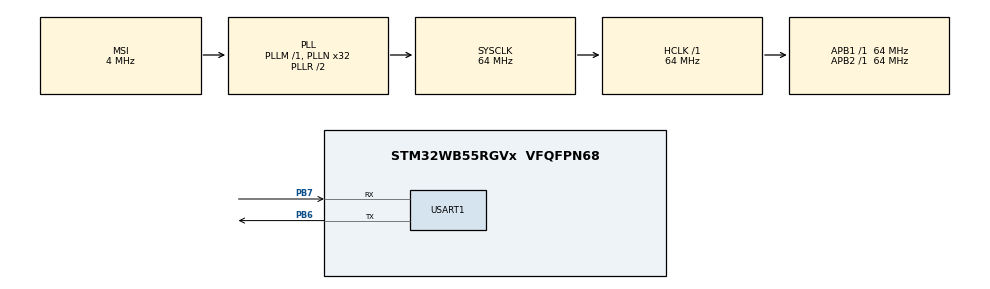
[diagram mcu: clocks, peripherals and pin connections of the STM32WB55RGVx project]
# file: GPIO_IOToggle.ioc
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Mcu.Family=STM32WB
Mcu.Name=STM32WB55RGVx
Mcu.Package=VFQFPN68
NVIC.PriorityGroup=NVIC_PRIORITYGROUP_4
PB6.Mode=Asynchronous
PB6.Signal=USART1_TX
PB7.Mode=Asynchronous
PB7.Signal=USART1_RX
ProjectManager.HeapSize=0x200
ProjectManager.StackSize=0x400
ProjectManager.TargetToolchain=STM32CubeIDE
RCC.ADCFreq_Value=16000000
RCC.AHB2CLKDivider=RCC_SYSCLK_DIV2
RCC.AHBFreq_Value=64000000
RCC.APB1Freq_Value=64000000
RCC.APB1TimFreq_Value=64000000
RCC.APB2Freq_Value=64000000
RCC.APB2TimFreq_Value=64000000
RCC.APB3Freq_Value=16000000
RCC.CodegenConfigPeriph=false
RCC.CortexFreq_Value=64000000
RCC.HCLKFreq_Value=64000000
RCC.HSE_VALUE=8000000
RCC.HSI48_VALUE=48000000
RCC.HSI_VALUE=16000000
RCC.LSE_VALUE=32768
RCC.MSI_VALUE=4000000
RCC.PLLN=32
RCC.PLLP=RCC_PLLP_DIV5
RCC.PLLQ=4
RCC.SYSCLKFreq_VALUE=64000000
RCC.SYSCLKSource=RCC_SYSCLKSOURCE_PLLCLK
RCC.USBFreq_Value=16000000
RCC.VCOOutputFreq_Value=128000000
USART1.VirtualMode-Asynchronous=VM_ASYNC
board=custom

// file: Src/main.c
/* USER CODE BEGIN Header */
/**
  ******************************************************************************
  * @file    GPIO/GPIO_IOToggle/Src/main.c
  * @author  MCD Application Team
  * @brief   This example describes how to configure and use GPIOs through
  *          the STM32WBxx HAL API.
  ******************************************************************************
  * @attention
  *
  * <h2><center>&copy; Copyright (c) 2019 STMicroelectronics.
  * All rights reserved.</center></h2>
  *
  * This software component is licensed by ST under BSD 3-Clause license,
  * the "License"; You may not use this file except in compliance with the
  * License. You may obtain a copy of the License at:
  *                        opensource.org/licenses/BSD-3-Clause
  *
  ******************************************************************************
  */
/* USER CODE END Header */
#include "main.h"

UART_HandleTypeDef huart1;

/* USER CODE BEGIN PV */
static GPIO_InitTypeDef  GPIO_InitStruct;

/* USER CODE END PV */

void SystemClock_Config(void);
static void MX_GPIO_Init(void);
static void MX_USART1_UART_Init(void);

int main(void)
{
  /* USER CODE BEGIN 1 */
  /* STM32WBxx HAL library initialization:
       - Configure the Flash prefetch
       - Systick timer is configured by default as source of time base, but user
         can eventually implement his proper time base source (a general purpose
         timer for example or other time source), keeping in mind that Time base
         duration should be kept 1ms since PPP_TIMEOUT_VALUEs are defined and
         handled in milliseconds basis.
       - Set NVIC Group Priority to 4
       - Low Level Initialization
     */
  /* USER CODE END 1 */

  /* MCU Configuration--------------------------------------------------------*/

  /* Reset of all peripherals, Initializes the Flash interface and the Systick. */
  HAL_Init();

  /* Configure the system clock */
  SystemClock_Config();

  /* Initialize all configured peripherals */
  MX_GPIO_Init();
  MX_USART1_UART_Init();
  /* USER CODE BEGIN 2 */

   /* -1- Enable GPIO Clock (to be able to program the configuration registers) */

  /* USER CODE END 2 */

  /* Infinite loop */
  while (1)
  {
  	uint8_t TxDataGP[32] = {0x55,0xAA,2,17,2,96,112,120,120,112,96,96,112,120,120,120,120,112,96,96,112,120,120,120,120,112,96,132,0,32,120,0,0,0,4,0,0,0};
  	HAL_UART_Transmit(&huart1, (uint8_t*)TxDataGP, 32,100);
    HAL_Delay(1000);

  }
  /* USER CODE END 3 */
}

void SystemClock_Config(void)
{
  RCC_OscInitTypeDef RCC_OscInitStruct = {0};
  RCC_ClkInitTypeDef RCC_ClkInitStruct = {0};

  /** Initializes the RCC Oscillators according to the specified parameters
  * in the RCC_OscInitTypeDef structure.
  */
  RCC_OscInitStruct.OscillatorType = RCC_OSCILLATORTYPE_MSI;
  RCC_OscInitStruct.MSIState = RCC_MSI_ON;
  RCC_OscInitStruct.MSICalibrationValue = RCC_MSICALIBRATION_DEFAULT;
  RCC_OscInitStruct.MSIClockRange = RCC_MSIRANGE_6;
  RCC_OscInitStruct.PLL.PLLState = RCC_PLL_ON;
  RCC_OscInitStruct.PLL.PLLSource = RCC_PLLSOURCE_MSI;
  RCC_OscInitStruct.PLL.PLLM = RCC_PLLM_DIV1;
  RCC_OscInitStruct.PLL.PLLN = 32;
  RCC_OscInitStruct.PLL.PLLP = RCC_PLLP_DIV5;
  RCC_OscInitStruct.PLL.PLLR = RCC_PLLR_DIV2;
  RCC_OscInitStruct.PLL.PLLQ = 4;
  if (HAL_RCC_OscConfig(&RCC_OscInitStruct) != HAL_OK)
  {
    Error_Handler();
  }
  /** Configure the SYSCLKSource, HCLK, PCLK1 and PCLK2 clocks dividers
  */
  RCC_ClkInitStruct.ClockType = RCC_CLOCKTYPE_HCLK4|RCC_CLOCKTYPE_HCLK2
                              |RCC_CLOCKTYPE_HCLK|RCC_CLOCKTYPE_SYSCLK
                              |RCC_CLOCKTYPE_PCLK1|RCC_CLOCKTYPE_PCLK2;
  RCC_ClkInitStruct.SYSCLKSource = RCC_SYSCLKSOURCE_PLLCLK;
  RCC_ClkInitStruct.AHBCLKDivider = RCC_SYSCLK_DIV1;
  RCC_ClkInitStruct.APB1CLKDivider = RCC_HCLK_DIV1;
  RCC_ClkInitStruct.APB2CLKDivider = RCC_HCLK_DIV1;
  RCC_ClkInitStruct.AHBCLK2Divider = RCC_SYSCLK_DIV2;
  RCC_ClkInitStruct.AHBCLK4Divider = RCC_SYSCLK_DIV1;

  if (HAL_RCC_ClockConfig(&RCC_ClkInitStruct, FLASH_LATENCY_3) != HAL_OK)
  {
    Error_Handler();
  }
  /** Initializes the peripherals clocks
  */
}

static void MX_USART1_UART_Init(void)
{

  huart1.Instance = USART1;
  huart1.Init.BaudRate = 115200;
  huart1.Init.WordLength = UART_WORDLENGTH_8B;
  huart1.Init.StopBits = UART_STOPBITS_1;
  huart1.Init.Parity = UART_PARITY_NONE;
  huart1.Init.Mode = UART_MODE_TX_RX;
  huart1.Init.HwFlowCtl = UART_HWCONTROL_NONE;
  huart1.Init.OverSampling = UART_OVERSAMPLING_16;
  huart1.Init.OneBitSampling = UART_ONE_BIT_SAMPLE_DISABLE;
  huart1.Init.ClockPrescaler = UART_PRESCALER_DIV1;
  huart1.AdvancedInit.AdvFeatureInit = UART_ADVFEATURE_NO_INIT;
  if (HAL_UART_Init(&huart1) != HAL_OK)
  {
    Error_Handler();
  }
  if (HAL_UARTEx_SetTxFifoThreshold(&huart1, UART_TXFIFO_THRESHOLD_1_8) != HAL_OK)
  {
    Error_Handler();
  }
  if (HAL_UARTEx_SetRxFifoThreshold(&huart1, UART_RXFIFO_THRESHOLD_1_8) != HAL_OK)
  {
    Error_Handler();
  }
  if (HAL_UARTEx_DisableFifoMode(&huart1) != HAL_OK)
  {
    Error_Handler();
  }

}

static void MX_GPIO_Init(void)
{

  /* GPIO Ports Clock Enable */
  __HAL_RCC_GPIOB_CLK_ENABLE();

}

void Error_Handler(void)
{
  while(1)
  {
  }
}

/************************ (C) COPYRIGHT STMicroelectronics *****END OF FILE****/
